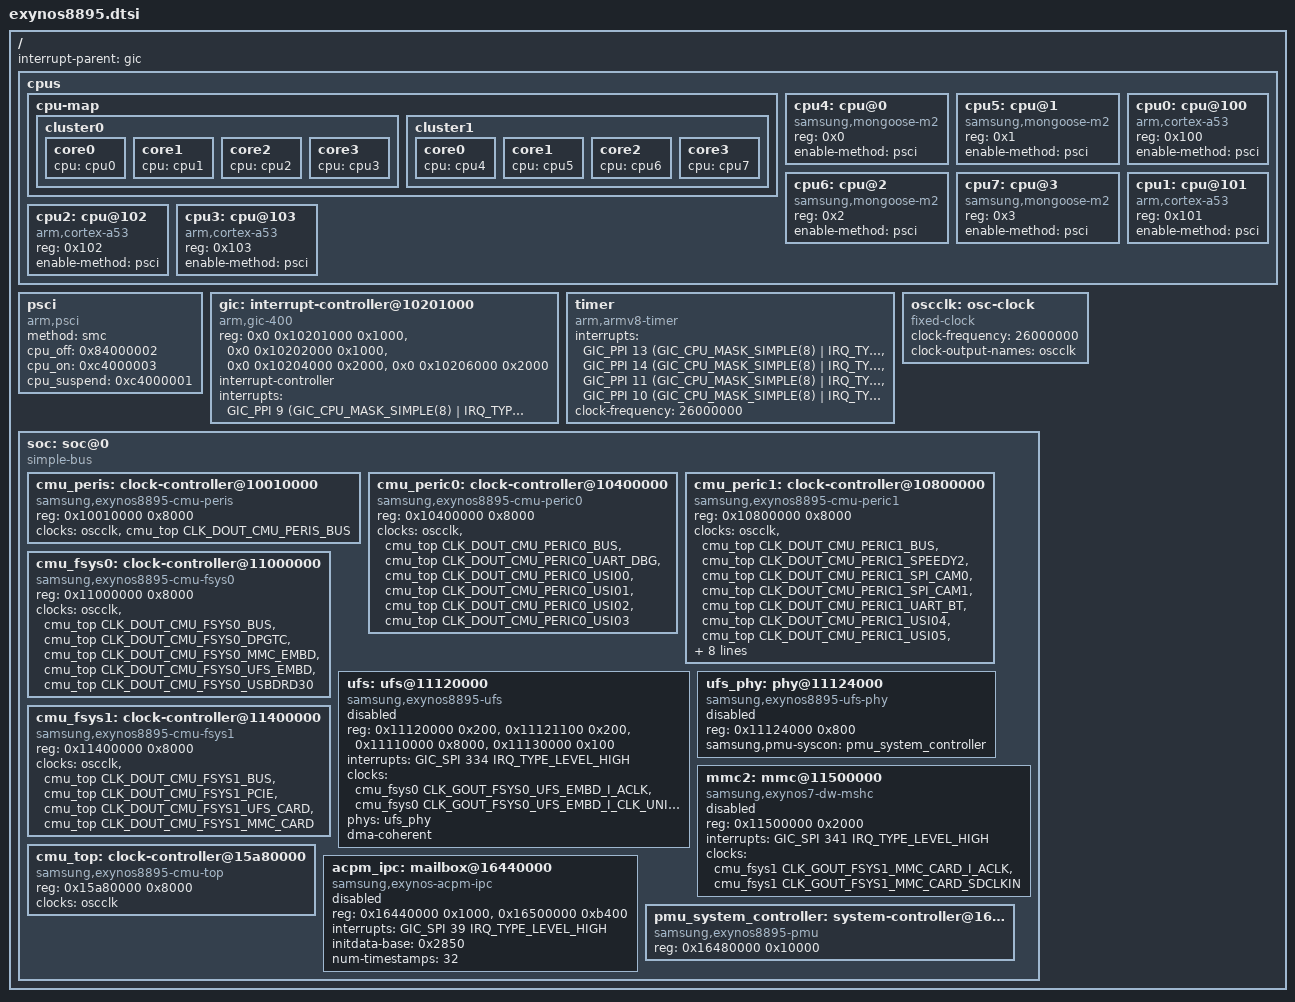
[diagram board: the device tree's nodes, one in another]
// SPDX-License-Identifier: GPL-2.0 OR BSD-3-Clause
/*
 * Samsung's Exynos 8895 SoC device tree source
 *
 * Copyright (c) 2024, Ivaylo Ivanov <ivo.ivanov.ivanov1@gmail.com>
 */

#include <dt-bindings/interrupt-controller/arm-gic.h>
#include <dt-bindings/clock/samsung,exynos8895.h>

/ {
	#address-cells = <2>;
	#size-cells = <1>;
	interrupt-parent = <&gic>;

	cpus {
		#address-cells = <1>;
		#size-cells = <0>;

		cpu-map {
			cluster0 {
				core0 {
					cpu = <&cpu0>;
				};
				core1 {
					cpu = <&cpu1>;
				};
				core2 {
					cpu = <&cpu2>;
				};
				core3 {
					cpu = <&cpu3>;
				};
			};

			cluster1 {
				core0 {
					cpu = <&cpu4>;
				};
				core1 {
					cpu = <&cpu5>;
				};
				core2 {
					cpu = <&cpu6>;
				};
				core3 {
					cpu = <&cpu7>;
				};
			};
		};

		cpu4: cpu@0 {
			device_type = "cpu";
			compatible = "samsung,mongoose-m2";
			reg = <0x0>;
			enable-method = "psci";
		};

		cpu5: cpu@1 {
			device_type = "cpu";
			compatible = "samsung,mongoose-m2";
			reg = <0x1>;
			enable-method = "psci";
		};

		cpu6: cpu@2 {
			device_type = "cpu";
			compatible = "samsung,mongoose-m2";
			reg = <0x2>;
			enable-method = "psci";
		};

		cpu7: cpu@3 {
			device_type = "cpu";
			compatible = "samsung,mongoose-m2";
			reg = <0x3>;
			enable-method = "psci";
		};

		cpu0: cpu@100 {
			device_type = "cpu";
			compatible = "arm,cortex-a53";
			reg = <0x100>;
			enable-method = "psci";
		};

		cpu1: cpu@101 {
			device_type = "cpu";
			compatible = "arm,cortex-a53";
			reg = <0x101>;
			enable-method = "psci";
		};

		cpu2: cpu@102 {
			device_type = "cpu";
			compatible = "arm,cortex-a53";
			reg = <0x102>;
			enable-method = "psci";
		};

		cpu3: cpu@103 {
			device_type = "cpu";
			compatible = "arm,cortex-a53";
			reg = <0x103>;
			enable-method = "psci";
		};
	};

	psci {
		compatible = "arm,psci";
		method = "smc";
		cpu_off = <0x84000002>;
		cpu_on = <0xc4000003>;
		cpu_suspend = <0xc4000001>;
	};

	gic: interrupt-controller@10201000 {
		compatible = "arm,gic-400";
		reg = <0x0 0x10201000 0x1000>,
		      <0x0 0x10202000 0x1000>,
		      <0x0 0x10204000 0x2000>,
		      <0x0 0x10206000 0x2000>;
		#interrupt-cells = <3>;
		#address-cells = <0>;
		interrupt-controller;
		interrupts = <GIC_PPI 9 (GIC_CPU_MASK_SIMPLE(8) |
					IRQ_TYPE_LEVEL_HIGH)>;
	};

	timer {
		compatible = "arm,armv8-timer";
		/* Hypervisor Virtual Timer interrupt is not wired to GIC */
		interrupts = <GIC_PPI 13 (GIC_CPU_MASK_SIMPLE(8) | IRQ_TYPE_LEVEL_LOW)>,
			     <GIC_PPI 14 (GIC_CPU_MASK_SIMPLE(8) | IRQ_TYPE_LEVEL_LOW)>,
			     <GIC_PPI 11 (GIC_CPU_MASK_SIMPLE(8) | IRQ_TYPE_LEVEL_LOW)>,
			     <GIC_PPI 10 (GIC_CPU_MASK_SIMPLE(8) | IRQ_TYPE_LEVEL_LOW)>;
		/*
		 * Non-updatable, broken stock Samsung bootloader does not
		 * configure CNTFRQ_EL0
		 */
		clock-frequency = <26000000>;
	};
	oscclk: osc-clock {
		compatible = "fixed-clock";
		#clock-cells = <0>;
		clock-frequency = <26000000>;
		clock-output-names = "oscclk";
	};

	soc: soc@0 {
		compatible = "simple-bus";
		#address-cells = <1>;
		#size-cells = <1>;
		ranges = <0x0 0x0 0x0 0x20000000>;

		cmu_peris: clock-controller@10010000 {
			compatible = "samsung,exynos8895-cmu-peris";
			reg = <0x10010000 0x8000>;
			#clock-cells = <1>;
			clocks = <&oscclk>,
				 <&cmu_top CLK_DOUT_CMU_PERIS_BUS>;
			clock-names = "oscclk", "bus";
		};

		cmu_peric0: clock-controller@10400000 {
			compatible = "samsung,exynos8895-cmu-peric0";
			reg = <0x10400000 0x8000>;
			#clock-cells = <1>;
			clocks = <&oscclk>,
				 <&cmu_top CLK_DOUT_CMU_PERIC0_BUS>,
				 <&cmu_top CLK_DOUT_CMU_PERIC0_UART_DBG>,
				 <&cmu_top CLK_DOUT_CMU_PERIC0_USI00>,
				 <&cmu_top CLK_DOUT_CMU_PERIC0_USI01>,
				 <&cmu_top CLK_DOUT_CMU_PERIC0_USI02>,
				 <&cmu_top CLK_DOUT_CMU_PERIC0_USI03>;
			clock-names = "oscclk", "bus", "uart", "usi0",
				      "usi1", "usi2", "usi3";
		};

		cmu_peric1: clock-controller@10800000 {
			compatible = "samsung,exynos8895-cmu-peric1";
			reg = <0x10800000 0x8000>;
			#clock-cells = <1>;
			clocks = <&oscclk>,
				 <&cmu_top CLK_DOUT_CMU_PERIC1_BUS>,
				 <&cmu_top CLK_DOUT_CMU_PERIC1_SPEEDY2>,
				 <&cmu_top CLK_DOUT_CMU_PERIC1_SPI_CAM0>,
				 <&cmu_top CLK_DOUT_CMU_PERIC1_SPI_CAM1>,
				 <&cmu_top CLK_DOUT_CMU_PERIC1_UART_BT>,
				 <&cmu_top CLK_DOUT_CMU_PERIC1_USI04>,
				 <&cmu_top CLK_DOUT_CMU_PERIC1_USI05>,
				 <&cmu_top CLK_DOUT_CMU_PERIC1_USI06>,
				 <&cmu_top CLK_DOUT_CMU_PERIC1_USI07>,
				 <&cmu_top CLK_DOUT_CMU_PERIC1_USI08>,
				 <&cmu_top CLK_DOUT_CMU_PERIC1_USI09>,
				 <&cmu_top CLK_DOUT_CMU_PERIC1_USI10>,
				 <&cmu_top CLK_DOUT_CMU_PERIC1_USI11>,
				 <&cmu_top CLK_DOUT_CMU_PERIC1_USI12>,
				 <&cmu_top CLK_DOUT_CMU_PERIC1_USI13>;
			clock-names = "oscclk", "bus", "speedy", "cam0",
				      "cam1", "uart", "usi4", "usi5",
				      "usi6", "usi7", "usi8", "usi9",
				      "usi10", "usi11", "usi12", "usi13";
		};

		cmu_fsys0: clock-controller@11000000 {
			compatible = "samsung,exynos8895-cmu-fsys0";
			reg = <0x11000000 0x8000>;
			#clock-cells = <1>;
			clocks = <&oscclk>,
				 <&cmu_top CLK_DOUT_CMU_FSYS0_BUS>,
				 <&cmu_top CLK_DOUT_CMU_FSYS0_DPGTC>,
				 <&cmu_top CLK_DOUT_CMU_FSYS0_MMC_EMBD>,
				 <&cmu_top CLK_DOUT_CMU_FSYS0_UFS_EMBD>,
				 <&cmu_top CLK_DOUT_CMU_FSYS0_USBDRD30>;
			clock-names = "oscclk", "bus", "dpgtc", "mmc",
				      "ufs", "usbdrd30";
		};

		/* Exynos8895 UFS v4: keep disabled until host and PHY are ported. */
		ufs: ufs@11120000 {
			compatible = "samsung,exynos8895-ufs";
			reg = <0x11120000 0x200>,
			      <0x11121100 0x200>,
			      <0x11110000 0x8000>,
			      <0x11130000 0x100>;
			reg-names = "hci", "vs_hci", "unipro", "ufsp";
			interrupts = <GIC_SPI 334 IRQ_TYPE_LEVEL_HIGH>;
			clocks = <&cmu_fsys0 CLK_GOUT_FSYS0_UFS_EMBD_I_ACLK>,
				 <&cmu_fsys0 CLK_GOUT_FSYS0_UFS_EMBD_I_CLK_UNIPRO>;
			clock-names = "core_clk", "sclk_unipro_main";
			phys = <&ufs_phy>;
			phy-names = "ufs-phy";
			dma-coherent;
			status = "disabled";
		};

		/* PMA aperture from the vendor Exynos8895 UFS v4 description. */
		ufs_phy: phy@11124000 {
			compatible = "samsung,exynos8895-ufs-phy";
			reg = <0x11124000 0x800>;
			reg-names = "phy-pma";
			#phy-cells = <0>;
			samsung,pmu-syscon = <&pmu_system_controller>;
			status = "disabled";
		};

		mmc2: mmc@11500000 {
			compatible = "samsung,exynos7-dw-mshc";
			reg = <0x11500000 0x2000>;
			interrupts = <GIC_SPI 341 IRQ_TYPE_LEVEL_HIGH>;
			clocks = <&cmu_fsys1 CLK_GOUT_FSYS1_MMC_CARD_I_ACLK>,
				 <&cmu_fsys1 CLK_GOUT_FSYS1_MMC_CARD_SDCLKIN>;
			clock-names = "biu", "ciu";
			#address-cells = <1>;
			#size-cells = <0>;
			status = "disabled";
		};

		cmu_fsys1: clock-controller@11400000 {
			compatible = "samsung,exynos8895-cmu-fsys1";
			reg = <0x11400000 0x8000>;
			#clock-cells = <1>;
			clocks = <&oscclk>,
				 <&cmu_top CLK_DOUT_CMU_FSYS1_BUS>,
				 <&cmu_top CLK_DOUT_CMU_FSYS1_PCIE>,
				 <&cmu_top CLK_DOUT_CMU_FSYS1_UFS_CARD>,
				 <&cmu_top CLK_DOUT_CMU_FSYS1_MMC_CARD>;
			clock-names = "oscclk", "bus", "pcie", "ufs", "mmc";
		};

		cmu_top: clock-controller@15a80000 {
			compatible = "samsung,exynos8895-cmu-top";
			reg = <0x15a80000 0x8000>;
			#clock-cells = <1>;
			clocks = <&oscclk>;
			clock-names = "oscclk";
		};

		/* Vendor firmware IPC ABI is not yet supported by this kernel. */
		acpm_ipc: mailbox@16440000 {
			compatible = "samsung,exynos-acpm-ipc";
			reg = <0x16440000 0x1000>, <0x16500000 0xb400>;
			interrupts = <GIC_SPI 39 IRQ_TYPE_LEVEL_HIGH>;
			initdata-base = <0x2850>;
			num-timestamps = <32>;
			status = "disabled";
		};

		pmu_system_controller: system-controller@16480000 {
			compatible = "samsung,exynos8895-pmu",
				     "samsung,exynos7-pmu", "syscon";
			reg = <0x16480000 0x10000>;
		};
	};
};
